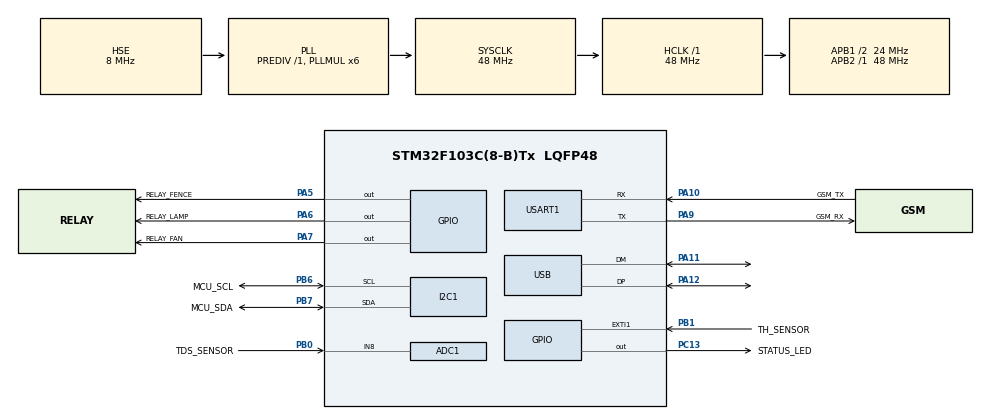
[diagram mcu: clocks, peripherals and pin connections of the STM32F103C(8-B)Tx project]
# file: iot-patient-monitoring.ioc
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ADC1.Channel-1\#ChannelRegularConversion=ADC_CHANNEL_8
ADC1.NbrOfConversionFlag=1
ADC1.Rank-1\#ChannelRegularConversion=1
ADC1.SamplingTime-1\#ChannelRegularConversion=ADC_SAMPLETIME_1CYCLE_5
ADC1.master=1
Mcu.Family=STM32F1
Mcu.Name=STM32F103C(8-B)Tx
Mcu.Package=LQFP48
NVIC.PriorityGroup=NVIC_PRIORITYGROUP_4
NVIC.USB_LP_CAN1_RX0_IRQn=true\:0\:0\:false\:false\:true\:false\:true\:true
PA10.GPIO_Label=GSM_TX
PA10.Mode=Asynchronous
PA10.Signal=USART1_RX
PA11.Mode=Device
PA11.Signal=USB_DM
PA12.Mode=Device
PA12.Signal=USB_DP
PA13.Mode=Serial_Wire
PA13.Signal=SYS_JTMS-SWDIO
PA14.Mode=Serial_Wire
PA14.Signal=SYS_JTCK-SWCLK
PA5.GPIO_Label=RELAY_FENCE
PA5.Signal=GPIO_Output
PA6.GPIO_Label=RELAY_LAMP
PA6.Signal=GPIO_Output
PA7.GPIO_Label=RELAY_FAN
PA7.Signal=GPIO_Output
PA9.GPIO_Label=GSM_RX
PA9.Mode=Asynchronous
PA9.Signal=USART1_TX
PB0.GPIO_Label=TDS_SENSOR
PB0.Signal=ADCx_IN8
PB1.GPIO_Label=TH_SENSOR
PB1.Signal=GPXTI1
PB6.GPIO_Label=MCU_SCL
PB6.Mode=I2C
PB6.Signal=I2C1_SCL
PB7.GPIO_Label=MCU_SDA
PB7.Mode=I2C
PB7.Signal=I2C1_SDA
PC13-TAMPER-RTC.GPIO_Label=STATUS_LED
PC13-TAMPER-RTC.Signal=GPIO_Output
PD0-OSC_IN.Mode=HSE-External-Oscillator
PD0-OSC_IN.Signal=RCC_OSC_IN
PD1-OSC_OUT.Mode=HSE-External-Oscillator
PD1-OSC_OUT.Signal=RCC_OSC_OUT
ProjectManager.HeapSize=0x200
ProjectManager.StackSize=0x400
ProjectManager.TargetToolchain=Makefile
RCC.ADCPresc=RCC_ADCPCLK2_DIV4
RCC.AHBFreq_Value=48000000
RCC.APB1CLKDivider=RCC_HCLK_DIV2
RCC.APB1Freq_Value=24000000
RCC.APB1TimFreq_Value=48000000
RCC.APB2Freq_Value=48000000
RCC.APB2TimFreq_Value=48000000
RCC.HCLKFreq_Value=48000000
RCC.PLLMUL=RCC_PLL_MUL6
RCC.SYSCLKFreq_VALUE=48000000
RCC.SYSCLKSource=RCC_SYSCLKSOURCE_PLLCLK
RCC.USBFreq_Value=48000000
SH.ADCx_IN8.0=ADC1_IN8,IN8
USART1.VirtualMode=VM_ASYNC
USB_DEVICE.CLASS_NAME_FS=CDC
USB_DEVICE.VirtualMode=Cdc
USB_DEVICE.VirtualModeFS=Cdc_FS
VP_USB_DEVICE_VS_USB_DEVICE_CDC_FS.Mode=CDC_FS
board=custom

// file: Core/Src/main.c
/* USER CODE BEGIN Header */
/**
  ******************************************************************************
  * @file           : main.c
  * @brief          : Main program body
  ******************************************************************************
  * @attention
  *
  * Copyright (c) 2026 STMicroelectronics.
  * All rights reserved.
  *
  * This software is licensed under terms that can be found in the LICENSE file
  * in the root directory of this software component.
  * If no LICENSE file comes with this software, it is provided AS-IS.
  *
  ******************************************************************************
  */
/* USER CODE END Header */
#include "main.h"
#include "usb_device.h"

ADC_HandleTypeDef hadc1;

I2C_HandleTypeDef hi2c1;

UART_HandleTypeDef huart1;

void SystemClock_Config(void);
static void MX_GPIO_Init(void);
static void MX_ADC1_Init(void);
static void MX_I2C1_Init(void);
static void MX_USART1_UART_Init(void);
/* USER CODE BEGIN PFP */
int _write(int file, char *ptr, int len){
    CDC_Transmit_FS((uint8_t*)ptr, len);
    return len;
  }
/* USER CODE END PFP */

int main(void)
{

  /* MCU Configuration--------------------------------------------------------*/

  /* Reset of all peripherals, Initializes the Flash interface and the Systick. */
  HAL_Init();

  /* Configure the system clock */
  SystemClock_Config();

  /* Initialize all configured peripherals */
  MX_GPIO_Init();
  MX_ADC1_Init();
  MX_I2C1_Init();
  MX_USART1_UART_Init();
  MX_USB_DEVICE_Init();
  /* USER CODE BEGIN 2 */
  HAL_GPIO_WritePin(STATUS_LED_GPIO_Port,STATUS_LED_Pin,GPIO_PIN_SET);
  /* USER CODE END 2 */

  /* Infinite loop */
  while (1)
  {
	  printf("Welcome STM32\n\r");
  }
}

void SystemClock_Config(void)
{
  RCC_OscInitTypeDef RCC_OscInitStruct = {0};
  RCC_ClkInitTypeDef RCC_ClkInitStruct = {0};
  RCC_PeriphCLKInitTypeDef PeriphClkInit = {0};

  /** Initializes the RCC Oscillators according to the specified parameters
  * in the RCC_OscInitTypeDef structure.
  */
  RCC_OscInitStruct.OscillatorType = RCC_OSCILLATORTYPE_HSE;
  RCC_OscInitStruct.HSEState = RCC_HSE_ON;
  RCC_OscInitStruct.HSEPredivValue = RCC_HSE_PREDIV_DIV1;
  RCC_OscInitStruct.HSIState = RCC_HSI_ON;
  RCC_OscInitStruct.PLL.PLLState = RCC_PLL_ON;
  RCC_OscInitStruct.PLL.PLLSource = RCC_PLLSOURCE_HSE;
  RCC_OscInitStruct.PLL.PLLMUL = RCC_PLL_MUL6;
  if (HAL_RCC_OscConfig(&RCC_OscInitStruct) != HAL_OK)
  {
    Error_Handler();
  }

  /** Initializes the CPU, AHB and APB buses clocks
  */
  RCC_ClkInitStruct.ClockType = RCC_CLOCKTYPE_HCLK|RCC_CLOCKTYPE_SYSCLK
                              |RCC_CLOCKTYPE_PCLK1|RCC_CLOCKTYPE_PCLK2;
  RCC_ClkInitStruct.SYSCLKSource = RCC_SYSCLKSOURCE_PLLCLK;
  RCC_ClkInitStruct.AHBCLKDivider = RCC_SYSCLK_DIV1;
  RCC_ClkInitStruct.APB1CLKDivider = RCC_HCLK_DIV2;
  RCC_ClkInitStruct.APB2CLKDivider = RCC_HCLK_DIV1;

  if (HAL_RCC_ClockConfig(&RCC_ClkInitStruct, FLASH_LATENCY_1) != HAL_OK)
  {
    Error_Handler();
  }
  PeriphClkInit.PeriphClockSelection = RCC_PERIPHCLK_ADC|RCC_PERIPHCLK_USB;
  PeriphClkInit.AdcClockSelection = RCC_ADCPCLK2_DIV4;
  PeriphClkInit.UsbClockSelection = RCC_USBCLKSOURCE_PLL;
  if (HAL_RCCEx_PeriphCLKConfig(&PeriphClkInit) != HAL_OK)
  {
    Error_Handler();
  }
}

static void MX_ADC1_Init(void)
{

  ADC_ChannelConfTypeDef sConfig = {0};

  /** Common config
  */
  hadc1.Instance = ADC1;
  hadc1.Init.ScanConvMode = ADC_SCAN_DISABLE;
  hadc1.Init.ContinuousConvMode = DISABLE;
  hadc1.Init.DiscontinuousConvMode = DISABLE;
  hadc1.Init.ExternalTrigConv = ADC_SOFTWARE_START;
  hadc1.Init.DataAlign = ADC_DATAALIGN_RIGHT;
  hadc1.Init.NbrOfConversion = 1;
  if (HAL_ADC_Init(&hadc1) != HAL_OK)
  {
    Error_Handler();
  }

  /** Configure Regular Channel
  */
  sConfig.Channel = ADC_CHANNEL_8;
  sConfig.Rank = ADC_REGULAR_RANK_1;
  sConfig.SamplingTime = ADC_SAMPLETIME_1CYCLE_5;
  if (HAL_ADC_ConfigChannel(&hadc1, &sConfig) != HAL_OK)
  {
    Error_Handler();
  }

}

static void MX_I2C1_Init(void)
{

  hi2c1.Instance = I2C1;
  hi2c1.Init.ClockSpeed = 100000;
  hi2c1.Init.DutyCycle = I2C_DUTYCYCLE_2;
  hi2c1.Init.OwnAddress1 = 0;
  hi2c1.Init.AddressingMode = I2C_ADDRESSINGMODE_7BIT;
  hi2c1.Init.DualAddressMode = I2C_DUALADDRESS_DISABLE;
  hi2c1.Init.OwnAddress2 = 0;
  hi2c1.Init.GeneralCallMode = I2C_GENERALCALL_DISABLE;
  hi2c1.Init.NoStretchMode = I2C_NOSTRETCH_DISABLE;
  if (HAL_I2C_Init(&hi2c1) != HAL_OK)
  {
    Error_Handler();
  }

}

static void MX_USART1_UART_Init(void)
{

  huart1.Instance = USART1;
  huart1.Init.BaudRate = 115200;
  huart1.Init.WordLength = UART_WORDLENGTH_8B;
  huart1.Init.StopBits = UART_STOPBITS_1;
  huart1.Init.Parity = UART_PARITY_NONE;
  huart1.Init.Mode = UART_MODE_TX_RX;
  huart1.Init.HwFlowCtl = UART_HWCONTROL_NONE;
  huart1.Init.OverSampling = UART_OVERSAMPLING_16;
  if (HAL_UART_Init(&huart1) != HAL_OK)
  {
    Error_Handler();
  }

}

static void MX_GPIO_Init(void)
{
  GPIO_InitTypeDef GPIO_InitStruct = {0};

  /* GPIO Ports Clock Enable */
  __HAL_RCC_GPIOC_CLK_ENABLE();
  __HAL_RCC_GPIOD_CLK_ENABLE();
  __HAL_RCC_GPIOA_CLK_ENABLE();
  __HAL_RCC_GPIOB_CLK_ENABLE();

  /*Configure GPIO pin Output Level */
  HAL_GPIO_WritePin(STATUS_LED_GPIO_Port, STATUS_LED_Pin, GPIO_PIN_RESET);

  /*Configure GPIO pin Output Level */
  HAL_GPIO_WritePin(GPIOA, RELAY_FENCE_Pin|RELAY_LAMP_Pin|RELAY_FAN_Pin, GPIO_PIN_RESET);

  /*Configure GPIO pin : STATUS_LED_Pin */
  GPIO_InitStruct.Pin = STATUS_LED_Pin;
  GPIO_InitStruct.Mode = GPIO_MODE_OUTPUT_PP;
  GPIO_InitStruct.Pull = GPIO_NOPULL;
  GPIO_InitStruct.Speed = GPIO_SPEED_FREQ_LOW;
  HAL_GPIO_Init(STATUS_LED_GPIO_Port, &GPIO_InitStruct);

  /*Configure GPIO pins : RELAY_FENCE_Pin RELAY_LAMP_Pin RELAY_FAN_Pin */
  GPIO_InitStruct.Pin = RELAY_FENCE_Pin|RELAY_LAMP_Pin|RELAY_FAN_Pin;
  GPIO_InitStruct.Mode = GPIO_MODE_OUTPUT_PP;
  GPIO_InitStruct.Pull = GPIO_NOPULL;
  GPIO_InitStruct.Speed = GPIO_SPEED_FREQ_LOW;
  HAL_GPIO_Init(GPIOA, &GPIO_InitStruct);

  /*Configure GPIO pin : TH_SENSOR_Pin */
  GPIO_InitStruct.Pin = TH_SENSOR_Pin;
  GPIO_InitStruct.Mode = GPIO_MODE_IT_RISING;
  GPIO_InitStruct.Pull = GPIO_NOPULL;
  HAL_GPIO_Init(TH_SENSOR_GPIO_Port, &GPIO_InitStruct);

}

void Error_Handler(void)
{
  __disable_irq();
  while (1)
  {
  }
}
